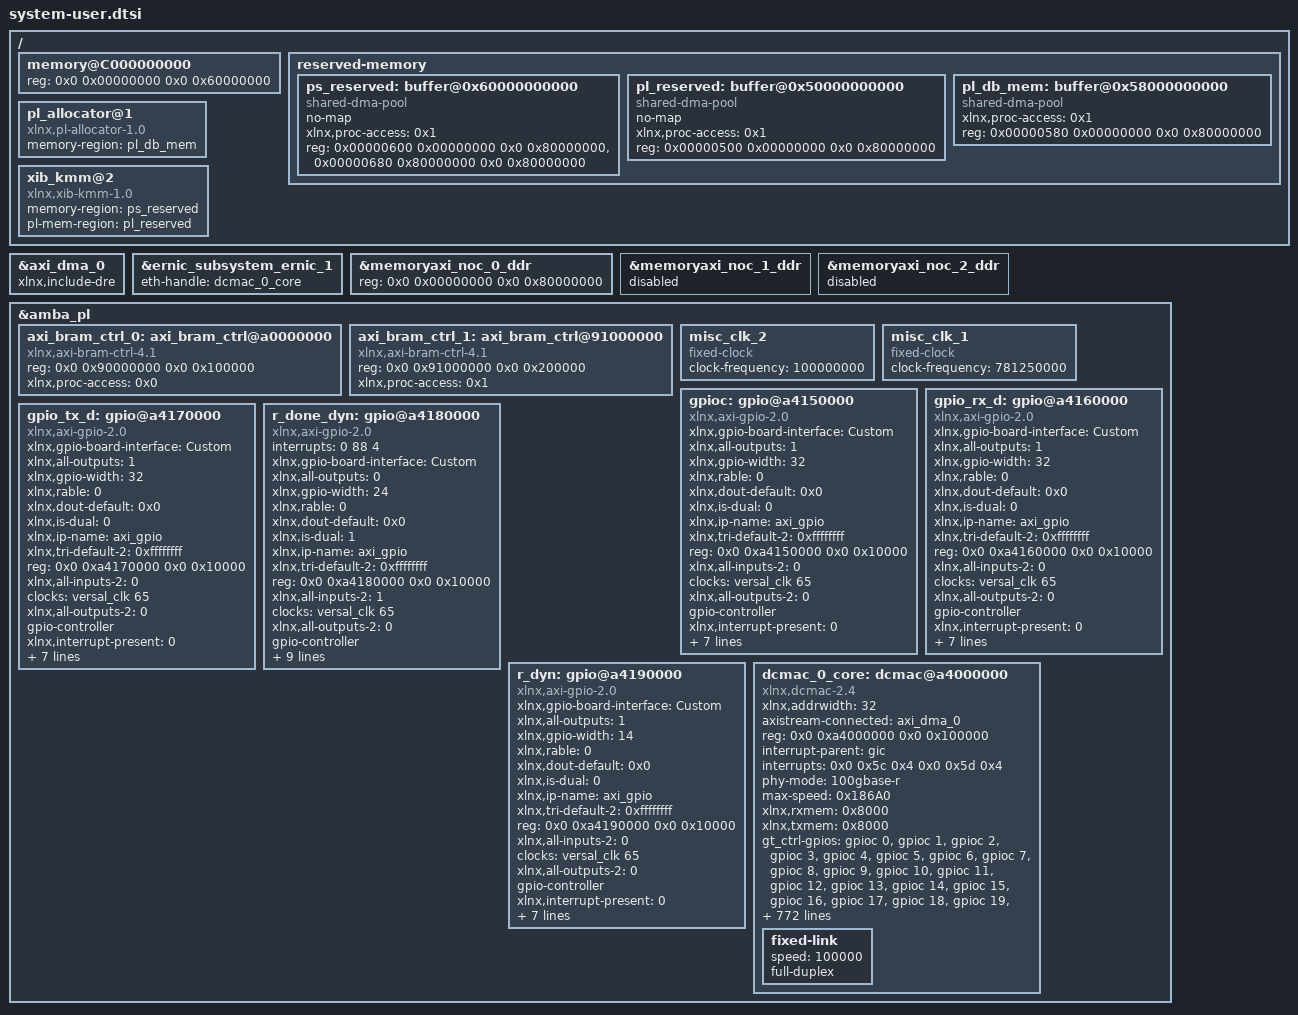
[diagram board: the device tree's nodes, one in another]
/ {
	memory@C000000000 {
		device_type = "memory";
		reg = <0x0 0x00000000 0x0 0x60000000>;
	};
	reserved-memory {
		#address-cells = <2>;
		#size-cells = <2>;
		ranges;

		/*ps_reserved: buffer@0x60000000 {
			compatible = "shared-dma-pool";
                        no-map;
			xlnx,proc-access = <0x1>;
			reg = <0x00000000 0x60000000 0x0 0x20000000>;
        	};*/

		ps_reserved: buffer@0x60000000000 {
			compatible = "shared-dma-pool";
                        no-map;
			xlnx,proc-access = <0x1>;
                        reg = <0x00000600 0x00000000 0x0 0x80000000>, <0x00000680 0x80000000 0x0 0x80000000>;
        	};

		/*pl_reserved: buffer@0x400000000 {
			compatible = "shared-dma-pool";
                        no-map;
			xlnx,proc-access = <0x1>;
			reg = <0xC0 0x00000000 0x1 0x7F000000>;
		};*/

		pl_reserved: buffer@0x50000000000 {
			compatible = "shared-dma-pool";
                        no-map;
			xlnx,proc-access = <0x1>;
                        reg = <0x00000500 0x00000000 0x0 0x80000000>;
                };

		/*pl_db_mem: buffer@0x45F000000 {
			compatible = "shared-dma-pool";
                        //no-map;
			xlnx,proc-access = <0x1>;
			reg = <0xC1 0x7F000000 0x0 0x1000000>;
		};*/

		pl_db_mem: buffer@0x58000000000 {
			compatible = "shared-dma-pool";
                        //no-map;
			xlnx,proc-access = <0x1>;
			reg = <0x00000580 0x00000000 0x0 0x80000000>;
		};
	};

	pl_allocator@1 {
		compatible = "xlnx,pl-allocator-1.0";
		memory-region = <&pl_db_mem>;
	};

	xib_kmm@2 {
		compatible = "xlnx,xib-kmm-1.0";
		memory-region = <&ps_reserved>;
		pl-mem-region = <&pl_reserved>;
	};
};
/*&cips_block_axi_gpio_gt_reset_mask {
	compatible = "xlnx,axi-gpio-2.0";
};
&cips_block_gtctrl {
	compatible = "xlnx,axi-gpio-2.0";
};
*/

&axi_dma_0 {
	xlnx,include-dre ;
};

&ernic_subsystem_ernic_1 {
	interrupt-names = "xrnic_intr0";
	eth-handle = <&dcmac_0_core>;
        //xlnx,num-qp = <0x800>;
};

&memoryaxi_noc_0_ddr {
	reg = <0x0 0x00000000 0x0 0x80000000>;
};
&memoryaxi_noc_1_ddr {
        status = "disabled";
};

&memoryaxi_noc_2_ddr {
        status = "disabled";
};

&amba_pl {
        axi_bram_ctrl_0: axi_bram_ctrl@a0000000 {
                compatible = "xlnx,axi-bram-ctrl-4.1";
                reg = <0x0 0x90000000 0x0 0x100000>;
                xlnx,proc-access = <0x0>;
        };
        axi_bram_ctrl_1: axi_bram_ctrl@91000000 {
                compatible = "xlnx,axi-bram-ctrl-4.1";
                reg = <0x0 0x91000000 0x0 0x200000>;
                xlnx,proc-access = <0x1>;
        };
	misc_clk_2: misc_clk_2 {
	            compatible = "fixed-clock";
		    clock-frequency = <100000000>;
		    #clock-cells = <0>;
        };
	misc_clk_1: misc_clk_1 {
		compatible = "fixed-clock";
		clock-frequency = <781250000>;
		#clock-cells = <0>;
	};
	/*misc_clk_0: misc_clk_0 {
		compatible = "fixed-clock";
		clock-frequency = <390625000>;
		#clock-cells = <0>;
	};*/
	gpioc: gpio@a4150000 {
		xlnx,gpio-board-interface = "Custom";
		compatible = "xlnx,axi-gpio-2.0" , "xlnx,xps-gpio-1.00.a" , "xlnx,xps-gpio-1.00.a";
		xlnx,all-outputs = <1>;
		#gpio-cells = <2>;
		xlnx,gpio-width = <32>;
		xlnx,rable = <0>;
		xlnx,dout-default = <0x0>;
		xlnx,is-dual = <0>;
		xlnx,ip-name = "axi_gpio";
		xlnx,tri-default-2 = <0xffffffff>;
		reg = <0x0 0xa4150000 0x0 0x10000>;
		xlnx,all-inputs-2 = <0>;
		clocks = <&versal_clk 65>;
		xlnx,all-outputs-2 = <0>;
		gpio-controller;
		xlnx,interrupt-present = <0>;
		xlnx,gpio2-board-interface = "Custom";
		xlnx,edk-iptype = "PERIPHERAL";
		xlnx,dout-default-2 = <0x0>;
		status = "okay";
		xlnx,gpio2-width = <32>;
		clock-names = "s_axi_aclk";
		xlnx,tri-default = <0xffffffff>;
		xlnx,name = "gpio1";
		xlnx,all-inputs = <0>;
	};

	gpio_rx_d: gpio@a4160000 {
		xlnx,gpio-board-interface = "Custom";
		compatible = "xlnx,axi-gpio-2.0" , "xlnx,xps-gpio-1.00.a" , "xlnx,xps-gpio-1.00.a";
		xlnx,all-outputs = <1>;
		#gpio-cells = <2>;
		xlnx,gpio-width = <32>;
		xlnx,rable = <0>;
		xlnx,dout-default = <0x0>;
		xlnx,is-dual = <0>;
		xlnx,ip-name = "axi_gpio";
		xlnx,tri-default-2 = <0xffffffff>;
		reg = <0x0 0xa4160000 0x0 0x10000>;
		xlnx,all-inputs-2 = <0>;
		clocks = <&versal_clk 65>;
		xlnx,all-outputs-2 = <0>;
		gpio-controller;
		xlnx,interrupt-present = <0>;
		xlnx,gpio2-board-interface = "Custom";
		xlnx,edk-iptype = "PERIPHERAL";
		xlnx,dout-default-2 = <0x0>;
		status = "okay";
		xlnx,gpio2-width = <32>;
		clock-names = "s_axi_aclk";
		xlnx,tri-default = <0xffffffff>;
		xlnx,name = "gpio_rx_d";
		xlnx,all-inputs = <0>;
	};

	gpio_tx_d: gpio@a4170000 {
		xlnx,gpio-board-interface = "Custom";
		compatible = "xlnx,axi-gpio-2.0" , "xlnx,xps-gpio-1.00.a" , "xlnx,xps-gpio-1.00.a";
		xlnx,all-outputs = <1>;
		#gpio-cells = <2>;
		xlnx,gpio-width = <32>;
		xlnx,rable = <0>;
		xlnx,dout-default = <0x0>;
		xlnx,is-dual = <0>;
		xlnx,ip-name = "axi_gpio";
		xlnx,tri-default-2 = <0xffffffff>;
		reg = <0x0 0xa4170000 0x0 0x10000>;
		xlnx,all-inputs-2 = <0>;
		clocks = <&versal_clk 65>;
		xlnx,all-outputs-2 = <0>;
		gpio-controller;
		xlnx,interrupt-present = <0>;
		xlnx,gpio2-board-interface = "Custom";
		xlnx,edk-iptype = "PERIPHERAL";
		xlnx,dout-default-2 = <0x0>;
		status = "okay";
		xlnx,gpio2-width = <32>;
		clock-names = "s_axi_aclk";
		xlnx,tri-default = <0xffffffff>;
		xlnx,name = "gpio_tx_d";
		xlnx,all-inputs = <0>;
	};

	r_done_dyn: gpio@a4180000 {
		#interrupt-cells = <2>;
		interrupts = < 0 88 4 >;
		xlnx,gpio-board-interface = "Custom";
		compatible = "xlnx,axi-gpio-2.0" , "xlnx,xps-gpio-1.00.a" , "xlnx,xps-gpio-1.00.a";
		xlnx,all-outputs = <0>;
		#gpio-cells = <2>;
		xlnx,gpio-width = <24>;
		//interrupt-parent = <&imux>;
		xlnx,rable = <0>;
		xlnx,dout-default = <0x0>;
		xlnx,is-dual = <1>;
		xlnx,ip-name = "axi_gpio";
		xlnx,tri-default-2 = <0xffffffff>;
		reg = <0x0 0xa4180000 0x0 0x10000>;
		xlnx,all-inputs-2 = <1>;
		clocks = <&versal_clk 65>;
		xlnx,all-outputs-2 = <0>;
		gpio-controller;
		xlnx,interrupt-present = <1>;
		xlnx,gpio2-board-interface = "Custom";
		xlnx,edk-iptype = "PERIPHERAL";
		xlnx,dout-default-2 = <0x0>;
		status = "okay";
		xlnx,gpio2-width = <24>;
		clock-names = "s_axi_aclk";
		interrupt-controller;
		interrupt-names = "ip2intc_irpt";
		xlnx,tri-default = <0xffffffff>;
		xlnx,name = "r_done_dyn";
		xlnx,all-inputs = <1>;
	};

	r_dyn: gpio@a4190000 {
		xlnx,gpio-board-interface = "Custom";
		compatible = "xlnx,axi-gpio-2.0" , "xlnx,xps-gpio-1.00.a" , "xlnx,xps-gpio-1.00.a";
		xlnx,all-outputs = <1>;
		#gpio-cells = <2>;
		xlnx,gpio-width = <14>;
		xlnx,rable = <0>;
		xlnx,dout-default = <0x0>;
		xlnx,is-dual = <0>;
		xlnx,ip-name = "axi_gpio";
		xlnx,tri-default-2 = <0xffffffff>;
		reg = <0x0 0xa4190000 0x0 0x10000>;
		xlnx,all-inputs-2 = <0>;
		clocks = <&versal_clk 65>;
		xlnx,all-outputs-2 = <0>;
		gpio-controller;
		xlnx,interrupt-present = <0>;
		xlnx,gpio2-board-interface = "Custom";
		xlnx,edk-iptype = "PERIPHERAL";
		xlnx,dout-default-2 = <0x0>;
		status = "okay";
		xlnx,gpio2-width = <32>;
		clock-names = "s_axi_aclk";
		xlnx,tri-default = <0xffffffff>;
		xlnx,name = "r_dyn";
		xlnx,all-inputs = <0>;
	};

        dcmac_0_core: dcmac@a4000000 {
                      xlnx,addrwidth = <32>;
                      axistream-connected = <&axi_dma_0>;
                      reg = <0x0 0xa4000000 0x0 0x100000>;
                      interrupt-parent = <&gic>;
                      interrupts = <0x0 0x5c 0x4 0x0 0x5d 0x4>;
                      phy-mode = "100gbase-r"; /* Interface mode specification */
                      max-speed = <0x186A0>;
                      xlnx,rxmem = <0x8000>;
                      xlnx,txmem = <0x8000>;
                      gt_ctrl-gpios = <&gpioc 0 0>, <&gpioc 1 0>, <&gpioc 2 0>, <&gpioc 3 0>, <&gpioc 4 0>, <&gpioc 5 0>, <&gpioc 6 0>, <&gpioc 7 0>,
                      <&gpioc 8 0>, <&gpioc 9 0>, <&gpioc 10 0>, <&gpioc 11 0>, <&gpioc 12 0>, <&gpioc 13 0>, <&gpioc 14 0>, <&gpioc 15 0>,
                      <&gpioc 16 0>, <&gpioc 17 0>, <&gpioc 18 0>, <&gpioc 19 0>, <&gpioc 20 0>, <&gpioc 21 0>, <&gpioc 22 0>, <&gpioc 23 0>,
                      <&gpioc 24 0>, <&gpioc 25 0>, <&gpioc 26 0>, <&gpioc 27 0>, <&gpioc 28 0>, <&gpioc 29 0>, <&gpioc 30 0>, <&gpioc 31 0>;

                      gt_rx_dpath-gpios = <&gpio_rx_d 0 0>, <&gpio_rx_d 1 0>, <&gpio_rx_d 2 0>, <&gpio_rx_d 3 0>, <&gpio_rx_d 4 0>, <&gpio_rx_d 5 0>, <&gpio_rx_d 6 0>, <&gpio_rx_d 7 0>,
                      <&gpio_rx_d 8 0>, <&gpio_rx_d 9 0>, <&gpio_rx_d 10 0>, <&gpio_rx_d 11 0>, <&gpio_rx_d 12 0>, <&gpio_rx_d 13 0>, <&gpio_rx_d 14 0>, <&gpio_rx_d 15 0>,
                      <&gpio_rx_d 16 0>, <&gpio_rx_d 17 0>, <&gpio_rx_d 18 0>, <&gpio_rx_d 19 0>, <&gpio_rx_d 20 0>, <&gpio_rx_d 21 0>, <&gpio_rx_d 22 0>;

                      gt_tx_dpath-gpios = <&gpio_tx_d 0 0>, <&gpio_tx_d 1 0>, <&gpio_tx_d 2 0>, <&gpio_tx_d 3 0>, <&gpio_tx_d 4 0>, <&gpio_tx_d 5 0>, <&gpio_tx_d 6 0>, <&gpio_tx_d 7 0>,
                      <&gpio_tx_d 8 0>, <&gpio_tx_d 9 0>, <&gpio_tx_d 10 0>, <&gpio_tx_d 11 0>, <&gpio_tx_d 12 0>, <&gpio_tx_d 13 0>, <&gpio_tx_d 14 0>, <&gpio_tx_d 15 0>,
                      <&gpio_tx_d 16 0>, <&gpio_tx_d 17 0>, <&gpio_tx_d 18 0>, <&gpio_tx_d 19 0>, <&gpio_tx_d 20 0>, <&gpio_tx_d 21 0>, <&gpio_tx_d 22 0>;

                      gt_tx_rst_done-gpios = <&r_done_dyn 0 0>, <&r_done_dyn 1 0>, <&r_done_dyn 2 0>, <&r_done_dyn 3 0>, <&r_done_dyn 4 0>, <&r_done_dyn 5 0>, <&r_done_dyn 6 0>, <&r_done_dyn 7 0>,
                      <&r_done_dyn 8 0>, <&r_done_dyn 9 0>, <&r_done_dyn 10 0>, <&r_done_dyn 11 0>, <&r_done_dyn 12 0>, <&r_done_dyn 13 0>, <&r_done_dyn 14 0>, <&r_done_dyn 15 0>,
                      <&r_done_dyn 16 0>, <&r_done_dyn 17 0>, <&r_done_dyn 18 0>, <&r_done_dyn 19 0>, <&r_done_dyn 20 0>, <&r_done_dyn 21 0>, <&r_done_dyn 22 0>, <&r_done_dyn 23 0>;

                      gt_rx_rst_done-gpios =  <&r_done_dyn 24 0>, <&r_done_dyn 25 0>, <&r_done_dyn 26 0>, <&r_done_dyn 27 0>,
                      <&r_done_dyn 28 0>, <&r_done_dyn 29 0>, <&r_done_dyn 30 0>, <&r_done_dyn 31 0>, <&r_done_dyn 32 0>, <&r_done_dyn 33 0>,
                      <&r_done_dyn 34 0>, <&r_done_dyn 35 0>, <&r_done_dyn 36 0>, <&r_done_dyn 37 0>, <&r_done_dyn 38 0>, <&r_done_dyn 39 0>,
                      <&r_done_dyn 40 0>, <&r_done_dyn 41 0>, <&r_done_dyn 42 0>, <&r_done_dyn 43 0>, <&r_done_dyn 44 0>, <&r_done_dyn 45 0>,
                      <&r_done_dyn 46 0>, <&r_done_dyn 47 0>;

                      gt_rsts-gpios = <&r_dyn 0 0>, <&r_dyn 1 0>, <&r_dyn 2 0>, <&r_dyn 3 0>, <&r_dyn 4 0>, <&r_dyn 5 0>, <&r_dyn 6 0>, <&r_dyn 7 0>,
                      <&r_dyn 8 0>, <&r_dyn 9 0>, <&r_dyn 10 0>, <&r_dyn 11 0>, <&r_dyn 12 0>, <&r_dyn 13 0>;

	              xlnx,gt-ch0-rx-user-data-width-c0 = <80>;
	              xlnx,gt-mode-0 = "NRZ";
	              xlnx,gt-ch0-rx-user-data-width-c1 = <80>;
	              xlnx,gt-mode-1 = "PAM4";
	              xlnx,mac-port5-enable-c0 = <0>;
	              xlnx,gt-mode-2 = "PAM4";
	              xlnx,mac-port5-enable-c1 = <1>;
	              xlnx,gt-mode-3 = "PAM4";
	              xlnx,mac-port0-rx-etype-gcp-c0 = <0x8808>;
	              xlnx,mac-port5-tx-sa-gpp-c0 = <0x0>;
	              xlnx,gt-mode-4 = "PAM4";
	              xlnx,mac-port0-rx-etype-gcp-c1 = <0x8808>;
	              xlnx,mac-port5-tx-sa-gpp-c1 = <0x0>;
	              xlnx,mac-port2-rx-etype-gcp-c0 = <0x8808>;
	              xlnx,gt-ch0-tx-int-data-width-c0 = <80>;
	              xlnx,mac-port1-rx-flow-c0 = <0>;
	              xlnx,mac-port2-rx-etype-gcp-c1 = <0x8808>;
	              xlnx,gt-ch0-tx-int-data-width-c1 = <80>;
	              xlnx,mac-port4-rx-etype-gcp-c0 = <0x8808>;
	              xlnx,mac-port3-tx-insert-c0 = <0>;
	              xlnx,mac-port1-rx-flow-c1 = <0>;
	              xlnx,mac-port4-rx-etype-gcp-c1 = <0x8808>;
	              xlnx,mac-port3-tx-insert-c1 = <1>;
	              xlnx,mac-port2-tx-ethertype-ppp-c0 = <0x8808>;
	              xlnx,gt-ch1-txprogdiv-freq-val-c0 = <0x266ac338>;
	              xlnx,mac-port2-tx-ethertype-ppp-c1 = <0x8808>;
	              xlnx,gt-ch1-txprogdiv-freq-val-c1 = <0x266ac338>;
	              xlnx,gt-ch2-rx-data-decoding-c0 = "RAW";
	              xlnx,port5-1588v2-operation-mode-c0 = "No , operation";
	              xlnx,gt-ch2-rx-data-decoding-c1 = "RAW";
	              xlnx,diffclk-board-interface = "Custom";
	              xlnx,port5-1588v2-operation-mode-c1 = "No , operation";
	              xlnx,oth-pcs-port0-config3-c0 = "N/A";
	              xlnx,mac-port4-tx-sa-ppp-c0 = <0x0>;
	              xlnx,oth-pcs-port0-config3-c1 = "100CAUI-4";
	              xlnx,mac-port4-tx-sa-ppp-c1 = <0x0>;
	              xlnx,mac-port4-rx-pause-da-ucast-c0 = <0x0>;
	              xlnx,mac-port4-rx-pause-da-ucast-c1 = <0x0>;
	              xlnx,mac-port0-rx-opcode-min-pcp-c0 = <0x0>;
	              xlnx,mac-port0-rx-opcode-min-pcp-c1 = <0x0>;
	              xlnx,overclocking = <0>;
	              xlnx,mac-port3-preemption-c0 = <0>;
	              xlnx,mac-port2-rx-opcode-max-pcp-c0 = <0xffff>;
	              xlnx,mac-port3-preemption-c1 = <0>;
	              xlnx,mac-port2-rx-opcode-max-pcp-c1 = <0xffff>;
	              xlnx,gt-ch0-tx-pll-type-c0 = "LCPLL";
	              xlnx,mac-port0-tx-opcode-ppp-c0 = <0x101>;
	              xlnx,gt-ch0-tx-pll-type-c1 = "LCPLL";
	              xlnx,oth-pcs-port2-config4-c0 = "N/A";
	              xlnx,mac-port0-tx-opcode-ppp-c1 = <0x101>;
	              xlnx,mac-port2-tx-ethertype-gpp-c0 = <0x8808>;
	              xlnx,oth-pcs-port2-config4-c1 = "100CAUI-4";
	              xlnx,mac-port4-config-c0 = "N/A";
	              xlnx,mac-port2-tx-ethertype-gpp-c1 = <0x8808>;
	              xlnx,num-gt-channels-port0 = <4>;
	              xlnx,mac-port4-config-c1 = "N/A";
	              xlnx,num-gt-channels-port1 = <0>;
	              xlnx,num-gt-channels-port2 = <0>;
	              xlnx,mac-port4-tx-sa-gpp-c0 = <0x0>;
	              xlnx,num-gt-channels-port3 = <0>;
	              xlnx,mac-port4-tx-sa-gpp-c1 = <0x0>;
	              xlnx,num-gt-channels-port4 = <0>;
	              xlnx,mac-port3-rx-pause-da-mcast-c0 = <0x180 0xc2000001>;
	              xlnx,num-gt-channels-port5 = <0>;
	              xlnx,port0-1588v2-operation-mode-c0 = "No , operation";
	              xlnx,mac-port3-rx-pause-da-mcast-c1 = <0x180 0xc2000001>;
	              xlnx,mac-port2-tx-insert-c0 = <0>;
	              xlnx,gt-ch2-rx-outclk-source-c0 = "RXPROGDIVCLK";
	              xlnx,port2-1588v2-clocking-c0 = "Ordinary/Boundary , Clock";
	              xlnx,port0-1588v2-operation-mode-c1 = "No , operation";
	              xlnx,mac-port2-tx-insert-c1 = <1>;
	              xlnx,name = "dcmac_0_core";
	              xlnx,mac-port0-rx-opcode-min-gcp-c0 = <0x0>;
	              xlnx,mac-port2-rx-flow-c0 = <0>;
	              xlnx,gt-ch2-txprogdiv-freq-source-c0 = "LCPLL";
	              xlnx,gt-ch2-rx-outclk-source-c1 = "RXPROGDIVCLK";
	              xlnx,port2-1588v2-clocking-c1 = "Ordinary/Boundary , Clock";
	              xlnx,mac-port0-rx-opcode-min-gcp-c1 = <0x0>;
	              xlnx,mac-port2-rx-flow-c1 = <0>;
	              xlnx,gt-ch2-txprogdiv-freq-source-c1 = "LCPLL";
	              xlnx,mac-port0-rx-etype-ppp-c0 = <0x8808>;
	              xlnx,mac-port0-rx-etype-ppp-c1 = <0x8808>;
	              xlnx,gt-drp-clk-c0 = <100>;
	              xlnx,mac-port3-tx-sa-ppp-c0 = <0x0>;
	              xlnx,gt-mode-dyn = "MIX";
	              xlnx,mac-port2-rx-etype-ppp-c0 = <0x8808>;
	              xlnx,mac-port2-rx-opcode-max-gcp-c0 = <0xffff>;
	              xlnx,gt-drp-clk-c1 = <100>;
	              xlnx,gt-ch2-tx-user-data-width-c0 = <80>;
	              xlnx,mac-port3-tx-sa-ppp-c1 = <0x0>;
	              xlnx,mac-port2-rx-etype-ppp-c1 = <0x8808>;
	              xlnx,mac-port2-rx-opcode-max-gcp-c1 = <0xffff>;
	              xlnx,gt-ch2-tx-user-data-width-c1 = <80>;
	              xlnx,oth-pcs-port1-config3-c0 = "N/A";
	              xlnx,mac-port4-rx-etype-ppp-c0 = <0x8808>;
	              xlnx,mac-port0-tx-opcode-gpp-c0 = <0x1>;
	              xlnx,oth-pcs-port1-config3-c1 = "100CAUI-4";
	              xlnx,mac-port5-tx-da-ppp-c0 = <0x180 0xc2000001>;
	              xlnx,mac-port4-rx-etype-ppp-c1 = <0x8808>;
	              xlnx,mac-port0-tx-opcode-gpp-c1 = <0x1>;
	              xlnx,gt-ch3-txprogdiv-freq-enable-c0;
	              xlnx,mac-port5-tx-da-ppp-c1 = <0x180 0xc2000001>;
	              xlnx,gt-ch3-txprogdiv-freq-enable-c1;
	              xlnx,mac-port2-tx-opcode-ppp-c0 = <0x101>;
	              xlnx,mac-port5-rx-pause-sa-c0 = <0x0>;
	              xlnx,mac-port3-tx-ethertype-ppp-c0 = <0x8808>;
	              xlnx,mac-port2-tx-opcode-ppp-c1 = <0x101>;
	              xlnx,mac-port5-rx-pause-sa-c1 = <0x0>;
	              xlnx,gt-ch1-rx-buffer-mode-c0 = <1>;
	              xlnx,port5-1588v2-clocking-c0 = "Ordinary/Boundary , Clock";
	              xlnx,mac-port3-tx-ethertype-ppp-c1 = <0x8808>;
	              xlnx,gt-ch1-rx-buffer-mode-c1 = <1>;
	              xlnx,port5-1588v2-clocking-c1 = "Ordinary/Boundary , Clock";
	              xlnx,gt-ch3-rx-data-decoding-c0 = "RAW";
	              xlnx,gt-ch1-tx-buffer-mode-c0 = <1>;
	              clock-names = "rx_axi_clk" , "rx_core_clk" , "rx_flexif_clk" , "rx_macif_clk" , "s_axi_aclk" , "ts_clk" , "tx_axi_clk" , "tx_core_clk" , "tx_flexif_clk" , "tx_macif_clk";
	              xlnx,gt-ch3-rx-data-decoding-c1 = "RAW";
	              xlnx,gt-ch1-tx-buffer-mode-c1 = <1>;
	              xlnx,mac-port0-enable-c0 = <1>;
	              xlnx,mac-port1-rx-opcode-ppp-c0 = <0x101>;
	              xlnx,gt-ch2-rxprogdiv-freq-source-c0 = "LCPLL";
	              xlnx,mac-port0-enable-c1 = <1>;
	              xlnx,mac-port1-rx-opcode-ppp-c1 = <0x101>;
	              xlnx,gtm-group-select2-c0 = "GTM_DUAL_X0Y0";
	              xlnx,gt-ch2-rxprogdiv-freq-source-c1 = "LCPLL";
	              xlnx,gt-ch1-tx-int-data-width-c0 = <80>;
	              xlnx,gtm-group-select2-c1 = "GTM_DUAL_X0Y0";
	              xlnx,gt-ch1-tx-int-data-width-c1 = <80>;
	              xlnx,ethernet-board-interface = "Custom";
	              xlnx,oth-pcs-port3-config4-c0 = "N/A";
	              xlnx,mac-port0-rx-etype-gpp-c0 = <0x8808>;
	              xlnx,oth-pcs-port3-config4-c1 = "100CAUI-4";
	              xlnx,mac-port0-rx-etype-gpp-c1 = <0x8808>;
	              xlnx,mac-port3-tx-sa-gpp-c0 = <0x0>;
	              xlnx,mac-port2-rx-etype-gpp-c0 = <0x8808>;
	              xlnx,data-rate-cfg-0 = "100G";
	              xlnx,oth-pcs-port0-config2-c0 = "N/A";
	              xlnx,mac-port3-tx-sa-gpp-c1 = <0x0>;
	              xlnx,mac-port2-enable-time-stamping-c0 = <0>;
	              xlnx,mac-port2-rx-etype-gpp-c1 = <0x8808>;
	              xlnx,num-gt-channels-port5-con1 = <0>;
	              xlnx,oth-pcs-port0-config2-c1 = "100CAUI-4";
	              xlnx,mac-port4-rx-etype-gpp-c0 = <0x8808>;
	              xlnx,mac-port2-enable-time-stamping-c1 = <0>;
	              xlnx,num-gt-channels-port5-con2 = <0>;
	              xlnx,gt-ch3-rxprogdiv-freq-enable-c0;
	              xlnx,mac-port5-tx-da-gpp-c0 = <0x180 0xc2000001>;
	              xlnx,mac-port4-rx-etype-gpp-c1 = <0x8808>;
	              xlnx,mac-port1-tx-insert-c0 = <0>;
	              xlnx,num-gt-channels-port5-con3 = <0>;
	              xlnx,gt-ch3-rxprogdiv-freq-enable-c1;
	              xlnx,mac-port5-tx-da-gpp-c1 = <0x180 0xc2000001>;
	              xlnx,mac-port1-tx-insert-c1 = <1>;
	              xlnx,num-gt-channels-port5-con4 = <0>;
	              xlnx,phy-operating-mode-c0 = "N/A";
	              xlnx,mac-port5-rx-pause-da-ucast-c0 = <0x0>;
	              xlnx,mac-port2-tx-opcode-gpp-c0 = <0x1>;
	              xlnx,gt-ch3-tx-refclk-frequency-c0 = <0x13356219>;
	              xlnx,gt-ch2-rxprogdiv-freq-val-c0 = <0x266ac338>;
	              xlnx,gt-ch0-tx-line-rate-c0 = <0x9d5b34>;
	              xlnx,mac-port5-rx-pause-da-ucast-c1 = <0x0>;
	              xlnx,mac-port3-tx-ethertype-gpp-c0 = <0x8808>;
	              xlnx,mac-port3-rx-flow-c0 = <0>;
	              xlnx,mac-port2-tx-opcode-gpp-c1 = <0x1>;
	              xlnx,num-gt-channels-port2-con1 = <0>;
	              xlnx,gt-ch3-tx-refclk-frequency-c1 = <0x9502f90>;
	              xlnx,gt-ch2-rxprogdiv-freq-val-c1 = <0x266ac338>;
	              xlnx,gt-ch0-tx-line-rate-c1 = <0x9d5b34>;
	              xlnx,mac-port3-tx-ethertype-gpp-c1 = <0x8808>;
	              xlnx,mac-port3-rx-flow-c1 = <0>;
	              xlnx,mac-port1-rx-opcode-min-pcp-c0 = <0x0>;
	              xlnx,num-gt-channels-port2-con2 = <0>;
	              lnx,gt-ch2-tx-line-rate-c0 = <0x9d5b34>;
	              xlnx,mac-port4-tx-opcode-ppp-c0 = <0x101>;
	              xlnx,mac-port2-tx-sa-ppp-c0 = <0x0>;
	              xlnx,mac-port1-rx-opcode-min-pcp-c1 = <0x0>;
	              xlnx,num-gt-channels-port2-con3 = <0>;
	              xlnx,gt-ch2-tx-line-rate-c1 = <0x9d5b34>;
	              xlnx,mac-port4-tx-opcode-ppp-c1 = <0x101>;
	              xlnx,mac-port2-tx-sa-ppp-c1 = <0x0>;
	              xlnx,num-gt-channels-port2-con4 = <0>;
	              xlnx,mac-port1-rx-opcode-gpp-c0 = <0x1>;
	              xlnx,mac-port4-tx-da-ppp-c0 = <0x180 0xc2000001>;
	              xlnx,mac-port3-rx-opcode-max-pcp-c0 = <0xffff>;
	              xlnx,mac-port1-rx-opcode-gpp-c1 = <0x1>;
	              xlnx,oth-pcs-port2-config3-c0 = "N/A";
	              xlnx,mac-port4-tx-da-ppp-c1 = <0x180 0xc2000001>;
	              xlnx,mac-port3-rx-opcode-max-pcp-c1 = <0xffff>;
	              xlnx,gt-ch2-tx-refclk-frequency-c0 = <0x13356219>;
	              xlnx,oth-pcs-port2-config3-c1 = "100CAUI-4";
	              xlnx,mac-port3-rx-opcode-ppp-c0 = <0x101>;
	              xlnx,gt-ch3-rx-outclk-source-c0 = "RXPROGDIVCLK";
	              xlnx,gt-ch2-tx-refclk-frequency-c1 = <0x9502f90>;
	              xlnx,mac-port3-rx-opcode-ppp-c1 = <0x101>;
	              xlnx,gt-ch3-tx-pll-type-c0 = "LCPLL";
	              xlnx,gt-ch3-rx-outclk-source-c1 = "RXPROGDIVCLK";
	              xlnx,gt-ch3-tx-pll-type-c1 = "LCPLL";
	              xlnx,gt-ch0-tx-user-data-width-c0 = <80>;
	              xlnx,port4-1588v2-operation-mode-c0 = "No , operation";
	              xlnx,gt-ch0-tx-user-data-width-c1 = <80>;
	              xlnx,port4-1588v2-operation-mode-c1 = "No , operation";
	              xlnx,mac-port5-rx-strip-c0 = <0>;
	              xlnx,mac-port4-preemption-c0 = <0>;
	              xlnx,mac-port1-rx-pause-sa-c0 = <0x0>;
	              xlnx,mac-port5-rx-strip-c1 = <0>;
	              xlnx,mac-port4-preemption-c1 = <0>;
	              xlnx,mac-port1-rx-pause-sa-c1 = <0x0>;
	              xlnx,gt-ch1-tx-refclk-frequency-c0 = <0x13356219>;
	              xlnx,mac-port4-rx-pause-da-mcast-c0 = <0x180 0xc2000001>;
	              xlnx,gt-ch1-tx-refclk-frequency-c1 = <0x9502f90>;
	              xlnx,mac-port4-rx-pause-da-mcast-c1 = <0x180 0xc2000001>;
	              xlnx,mac-port1-rx-opcode-min-gcp-c0 = <0x0>;
	              xlnx,oth-pcs-port4-config4-c0 = "N/A";
	              xlnx,mac-port4-tx-opcode-gpp-c0 = <0x1>;
	              xlnx,mac-port2-tx-sa-gpp-c0 = <0x0>;
	              xlnx,mac-port1-rx-opcode-min-gcp-c1 = <0x0>;
	              xlnx,oth-pcs-port4-config4-c1 = "100CAUI-4";
	              xlnx,mac-port4-tx-opcode-gpp-c1 = <0x1>;
	              xlnx,mac-port4-tx-ethertype-ppp-c0 = <0x8808>;
	              xlnx,mac-port2-tx-sa-gpp-c1 = <0x0>;
	              xlnx,mac-port4-tx-ethertype-ppp-c1 = <0x8808>;
	              xlnx,fec-slice5-cfg-c0 = "N/A";
	              xlnx,oth-pcs-port1-config2-c0 = "N/A";
	              xlnx,mac-port4-tx-da-gpp-c0 = <0x180 0xc2000001>;
	              xlnx,mac-port3-rx-opcode-max-gcp-c0 = <0xffff>;
	              xlnx,fec-slice5-cfg-c1 = "N/A";
	              xlnx,mac-port0-tx-insert-c0 = <1>;
	              xlnx,gt-ch0-tx-refclk-frequency-c0 = <0x13356219>;
	              xlnx,oth-pcs-port1-config2-c1 = "100CAUI-4";
	              xlnx,mac-port4-tx-da-gpp-c1 = <0x180 0xc2000001>;
	              xlnx,mac-port3-rx-opcode-max-gcp-c1 = <0xffff>;
	              xlnx,mac-port0-tx-insert-c1 = <1>;
	              xlnx,gt-ch0-tx-refclk-frequency-c1 = <0x9502f90>;
	              xlnx,mac-port3-rx-opcode-gpp-c0 = <0x1>;
	              xlnx,mac-port3-rx-opcode-gpp-c1 = <0x1>;
	              xlnx,mac-port2-enable-c0 = <0>;
	              xlnx,gt-pipeline-stages = <0>;
	              xlnx,mac-port2-enable-c1 = <1>;
	              xlnx,mac-port5-rx-opcode-ppp-c0 = <0x101>;
	              xlnx,mac-port4-rx-flow-c0 = <0>;
	              xlnx,mac-port1-tx-sa-ppp-c0 = <0x0>;
	              xlnx,mac-port5-rx-opcode-ppp-c1 = <0x101>;
	              xlnx,mac-port4-rx-flow-c1 = <0>;
	              xlnx,mac-port1-tx-sa-ppp-c1 = <0x0>;
	              xlnx,gt-ch3-rx-user-data-width-c0 = <80>;
	              xlnx,gt-ch3-rx-user-data-width-c1 = <80>;
	              xlnx,gt-ch0-rx-int-data-width-c0 = <80>;
	              xlnx,mac-port3-tx-da-ppp-c0 = <0x180 0xc2000001>;
	              xlnx,gt-ch0-rx-int-data-width-c1 = <80>;
	              xlnx,mac-port3-tx-da-ppp-c1 = <0x180 0xc2000001>;
	              xlnx,gtm-group-select1-c0 = "GTM_DUAL_X0Y0";
	              xlnx,gt-ch0-rxprogdiv-freq-val-c0 = <0x266ac338>;
	              xlnx,gtm-group-select1-c1 = "GTM_DUAL_X0Y0";
	              xlnx,gt-ch1-txprogdiv-freq-source-c0 = "LCPLL";
	              xlnx,gt-ch1-rx-line-rate-c0 = <0x9d5b34>;
	              xlnx,gt-ch0-rxprogdiv-freq-val-c1 = <0x266ac338>;
	              xlnx,oth-pcs-port3-config3-c0 = "N/A";
	              xlnx,include-auto-neg-lt-logic-c0 = "None";
	              xlnx,gt-ch2-tx-int-data-width-c0 = <80>;
	              xlnx,gt-ch1-txprogdiv-freq-source-c1 = "LCPLL";
	              xlnx,gt-ch1-rx-line-rate-c1 = <0x9d5b34>;
	              xlnx,full-density-mode = <0>;
	              xlnx,oth-pcs-port3-config3-c1 = "100CAUI-4";
	              xlnx,include-auto-neg-lt-logic-c1 = "None";
	              xlnx,gt-ch3-rx-line-rate-c0 = <0x9d5b34>;
	              xlnx,gt-ch2-tx-int-data-width-c1 = <80>;
	              xlnx,gt-ch0-rx-buffer-mode-c0 = <1>;
	              xlnx,mac-port4-tx-ethertype-gpp-c0 = <0x8808>;
	              xlnx,fec-slice3-cfg-c0 = "N/A";
	              xlnx,gt-ch3-rx-line-rate-c1 = <0x9d5b34>;
	              xlnx,gt-ch0-rx-buffer-mode-c1 = <1>;
	              xlnx,oth-pcs-port0-config1-c0 = "N/A";
	              xlnx,mac-port4-tx-ethertype-gpp-c1 = <0x8808>;
	              xlnx,fec-slice3-cfg-c1 = "N/A";
	              xlnx,gt-ch0-tx-buffer-mode-c0 = <1>;
	              xlnx,oth-pcs-port0-config1-c1 = "100CAUI-4";
	              xlnx,gt-ch0-tx-buffer-mode-c1 = <1>;
	              status = "okay";
	              xlnx,num-gt-channels-con4-valid = <0>;
	              xlnx,dcmac-clients-c0 = "N/A";
	              xlnx,gt-ch2-txprogdiv-freq-enable-c0;
	              xlnx,dcmac-clients-c1 = "N/A";
	              xlnx,gt-ch2-txprogdiv-freq-enable-c1;
	              xlnx,mac-port5-rx-opcode-gpp-c0 = <0x1>;
	              xlnx,mac-port1-tx-sa-gpp-c0 = <0x0>;
	              xlnx,mac-port5-rx-opcode-gpp-c1 = <0x1>;
	              xlnx,mac-port1-tx-sa-gpp-c1 = <0x0>;
	              xlnx,lane1-gt-loc-c0 = "X0Y0";
	              xlnx,oth-pcs-port5-config4-c0 = "N/A";
	              xlnx,mac-port2-rx-opcode-min-pcp-c0 = <0x0>;
	              xlnx,lane1-gt-loc-c1 = "X0Y0";
	              xlnx,is-board-project = <1>;
	              xlnx,oth-pcs-port5-config4-c1 = "100CAUI-4";
	              xlnx,mac-port4-rx-strip-c0 = <0>;
	              xlnx,mac-port3-tx-da-gpp-c0 = <0x180 0xc2000001>;
	              xlnx,mac-port2-rx-opcode-min-pcp-c1 = <0x0>;
	              xlnx,mac-port4-rx-strip-c1 = <0>;
	              xlnx,mac-port3-tx-da-gpp-c1 = <0x180 0xc2000001>;
	              xlnx,gt-ch1-rxprogdiv-freq-source-c0 = "LCPLL";
	              xlnx,oth-pcs-port2-config2-c0 = "N/A";
	              xlnx,mac-port1-config-c0 = "N/A";
	              xlnx,gt-ch1-rxprogdiv-freq-source-c1 = "LCPLL";
	              xlnx,oth-pcs-port2-config2-c1 = "100CAUI-4";
	              xlnx,mac-port4-rx-opcode-max-pcp-c0 = <0xffff>;
	              xlnx,mac-port1-config-c1 = "N/A";
	              xlnx,mac-port4-rx-opcode-max-pcp-c1 = <0xffff>;
	              xlnx,fec-slice1-cfg-c0 = "N/A";
	              xlnx,fec-slice1-cfg-c1 = "N/A";
	              xlnx,mac-port0-tx-sa-ppp-c0 = <0x0>;
	              xlnx,mac-port0-tx-sa-ppp-c1 = <0x0>;
	              xlnx,edk-iptype = "PERIPHERAL";
	              xlnx,mac-port5-rx-flow-c0 = <0>;
	              xlnx,mac-port0-rx-pause-da-ucast-c0 = <0x0>;
	              xlnx,mac-port5-tx-ethertype-ppp-c0 = <0x8808>;
	              xlnx,mac-port5-rx-flow-c1 = <0>;
	              xlnx,mac-port0-rx-pause-da-ucast-c1 = <0x0>;
	              xlnx,mac-port2-tx-da-ppp-c0 = <0x180 0xc2000001>;
	              xlnx,num-gt-channels-con3-valid = <0>;
	              xlnx,gt-ch2-rxprogdiv-freq-enable-c0;
	              xlnx,mac-port5-tx-ethertype-ppp-c1 = <0x8808>;
	              xlnx,mac-port2-tx-da-ppp-c1 = <0x180 0xc2000001>;
	              xlnx,gt-ch2-rxprogdiv-freq-enable-c1;
	              xlnx,port0-1588v2-clocking-c0 = "Ordinary/Boundary , Clock";
	              xlnx,port0-1588v2-clocking-c1 = "Ordinary/Boundary , Clock";
	              xlnx,mac-port5-rx-pause-da-mcast-c0 = <0x180 0xc2000001>;
	              xlnx,mac-port4-rx-pause-sa-c0 = <0x0>;
	              xlnx,oth-pcs-port4-config3-c0 = "N/A";
	              xlnx,mac-port5-rx-pause-da-mcast-c1 = <0x180 0xc2000001>;
	              xlnx,mac-port4-rx-pause-sa-c1 = <0x0>;
	              xlnx,gt-ch1-rx-user-data-width-c0 = <80>;
	              xlnx,oth-pcs-port4-config3-c1 = "100CAUI-4";
	              xlnx,mac-port4-enable-c0 = <0>;
	              xlnx,mac-port2-rx-opcode-min-gcp-c0 = <0x0>;
	              xlnx,gt-ch1-rx-user-data-width-c1 = <80>;
	              xlnx,mac-port4-enable-c1 = <1>;
	              xlnx,mac-port1-enable-time-stamping-c0 = <0>;
	              xlnx,mac-port2-rx-opcode-min-gcp-c1 = <0x0>;
	              xlnx,oth-pcs-port1-config1-c0 = "N/A";
	              xlnx,mac-port1-enable-time-stamping-c1 = <0>;
	              xlnx,oth-pcs-port1-config1-c1 = "100CAUI-4";
	              xlnx,num-gt-channels-con0 = <4>;
	              xlnx,enable-phase-fifo = <0>;
	              xlnx,num-gt-channels-con1 = <0>;
	              xlnx,mac-port4-rx-opcode-max-gcp-c0 = <0xffff>;
	              xlnx,mac-port1-rx-etype-pcp-c0 = <0x8808>;
	              xlnx,mac-port5-preemption-c0 = <0>;
	              xlnx,num-gt-channels-con2 = <0>;
	              xlnx,mac-port5-enable-time-stamping-c0 = <0>;
	              xlnx,mac-port4-rx-opcode-max-gcp-c1 = <0xffff>;
	              xlnx,mac-port1-rx-etype-pcp-c1 = <0x8808>;
	              xlnx,mac-port5-preemption-c1 = <0>;
	              xlnx,num-gt-channels-con3 = <0>;
	              xlnx,mac-port5-enable-time-stamping-c1 = <0>;
	              xlnx,mac-port3-rx-etype-pcp-c0 = <0x8808>;
	              xlnx,mac-port0-tx-sa-gpp-c0 = <0x0>;
	              xlnx,port3-1588v2-clocking-c0 = "Ordinary/Boundary , Clock";
	              xlnx,num-gt-channels-con4 = <0>;
	              xlnx,mac-port3-rx-etype-pcp-c1 = <0x8808>;
	              xlnx,mac-port0-tx-sa-gpp-c1 = <0x0>;
	              xlnx,port3-1588v2-operation-mode-c0 = "No , operation";
	              xlnx,port3-1588v2-clocking-c1 = "Ordinary/Boundary , Clock";
	              xlnx,mac-port5-rx-etype-pcp-c0 = <0x8808>;
	              xlnx,gt-ch2-txprogdiv-freq-val-c0 = <0x266ac338>;
	              xlnx,port3-1588v2-operation-mode-c1 = "No , operation";
	              xlnx,mac-port5-tx-ethertype-gpp-c0 = <0x8808>;
	              xlnx,mac-port5-rx-etype-pcp-c1 = <0x8808>;
	              xlnx,mac-port2-tx-da-gpp-c0 = <0x180 0xc2000001>;
	              xlnx,num-gt-channels-con2-valid = <0>;
	              xlnx,gt-ch2-txprogdiv-freq-val-c1 = <0x266ac338>;
	              xlnx,mac-port5-tx-ethertype-gpp-c1 = <0x8808>;
	              xlnx,mac-port2-tx-da-gpp-c1 = <0x180 0xc2000001>;
	              xlnx,gt-ch1-rx-int-data-width-c0 = <80>;
	              xlnx,gt-ch1-rx-int-data-width-c1 = <80>;
	              xlnx,oth-pcs-port3-config2-c0 = "N/A";
	              xlnx,gt-ch0-tx-outclk-source-c0 = "TXPROGDIVCLK";
	              xlnx,oth-pcs-port3-config2-c1 = "100CAUI-4";
	              xlnx,mac-port0-tx-flow-c0 = <1>;
	              xlnx,gt-ch0-tx-outclk-source-c1 = "TXPROGDIVCLK";
	              xlnx,mac-port0-tx-flow-c1 = <0>;
	              xlnx,mac-port0-preemption-c0 = <0>;
	              xlnx,gt-ch3-tx-int-data-width-c0 = <80>;
	              xlnx,mac-port0-preemption-c1 = <0>;
	              xlnx,gt-ch3-tx-int-data-width-c1 = <80>;
	              xlnx,mac-port3-rx-strip-c0 = <0>;
	              xlnx,mac-port1-tx-da-ppp-c0 = <0x180 0xc2000001>;
	              xlnx,mac-port3-rx-strip-c1 = <0>;
	              xlnx,mac-port1-tx-da-ppp-c1 = <0x180 0xc2000001>;
	              xlnx,mac-port1-rx-etype-gcp-c0 = <0x8808>;
	              xlnx,mac-port1-rx-etype-gcp-c1 = <0x8808>;
	              xlnx,mac-port3-rx-etype-gcp-c0 = <0x8808>;
	              xlnx,mac-port3-rx-etype-gcp-c1 = <0x8808>;
	              xlnx,mac-port3-config-c0 = "N/A";
	              xlnx,gt-ch2-tx-pll-type-c0 = "LCPLL";
	              xlnx,mac-port5-rx-etype-gcp-c0 = <0x8808>;
	              xlnx,mac-port3-config-c1 = "N/A";
	              xlnx,gt-ch2-tx-pll-type-c1 = "LCPLL";
	              xlnx,oth-pcs-port5-config3-c0 = "N/A";
	              xlnx,mac-port5-rx-etype-gcp-c1 = <0x8808>;
	              xlnx,num-gt-channels-con1-valid = <0>;
	              xlnx,oth-pcs-port5-config3-c1 = "100CAUI-4";
	              xlnx,num-gt-channels-port4-con1 = <0>;
	              xlnx,mac-port3-rx-opcode-min-pcp-c0 = <0x0>;
	              xlnx,num-gt-channels-port4-con2 = <0>;
	              xlnx,mac-port0-rx-pause-sa-c0 = <0x0>;
	              xlnx,oth-pcs-port2-config1-c0 = "N/A";
	              xlnx,mac-port3-rx-opcode-min-pcp-c1 = <0x0>;
	              xlnx,num-gt-channels-port4-con3 = <0>;
	              xlnx,mac-port0-rx-pause-sa-c1 = <0x0>;
	              xlnx,gt-ch0-tx-data-encoding-c0 = "RAW";
	              xlnx,oth-pcs-port2-config1-c1 = "100CAUI-4";
	              xlnx,num-gt-channels-port4-con4 = <0>;
	              xlnx,gt-ch0-txprogdiv-freq-source-c0 = "LCPLL";
	              xlnx,gt-ch0-tx-data-encoding-c1 = "RAW";
	              xlnx,gt-ch0-txprogdiv-freq-source-c1 = "LCPLL";
	              xlnx,mac-port5-rx-opcode-max-pcp-c0 = <0xffff>;
	              xlnx,num-gt-channels-port1-con1 = <0>;
	              xlnx,mac-port5-rx-opcode-max-pcp-c1 = <0xffff>;
	              compatible = "xlnx,dcmac-2.4";
	              xlnx,num-gt-channels-port1-con2 = <0>;
	              xlnx,mac-port1-tx-da-gpp-c0 = <0x180 0xc2000001>;
	              xlnx,num-gt-channels-port1-con3 = <0>;
	              xlnx,mac-port1-tx-da-gpp-c1 = <0x180 0xc2000001>;
	              xlnx,num-gt-channels-port1-con4 = <0>;
	              xlnx,mac-port1-rx-pause-da-ucast-c0 = <0x0>;
	              xlnx,mac-port1-rx-pause-da-ucast-c1 = <0x0>;
	              xlnx,gt-ch3-tx-user-data-width-c0 = <80>;
	              xlnx,gt-ch1-txprogdiv-freq-enable-c0;
	              xlnx,gt-ch3-tx-user-data-width-c1 = <80>;
	              xlnx,gt-ch1-txprogdiv-freq-enable-c1;
	              xlnx,oth-pcs-port4-config2-c0 = "N/A";
	              xlnx,gt-ch0-txprogdiv-freq-val-c0 = <0x266ac338>;
	              xlnx,oth-pcs-port4-config2-c1 = "100CAUI-4";
	              xlnx,mac-port1-tx-flow-c0 = <0>;
	              xlnx,num-gt-channels-con0-valid = <4>;
	              xlnx,gt-ch0-txprogdiv-freq-val-c1 = <0x266ac338>;
	              xlnx,mac-port0-tx-da-ppp-c0 = <0x180 0xc2000001>;
	              xlnx,mac-port1-tx-flow-c1 = <0>;
	              xlnx,mac-port3-rx-opcode-min-gcp-c0 = <0x0>;
	              xlnx,mac-port0-tx-da-ppp-c1 = <0x180 0xc2000001>;
	              xlnx,mac-port3-rx-opcode-min-gcp-c1 = <0x0>;
	              xlnx,gt-ch0-rxprogdiv-freq-source-c0 = "LCPLL";
	              xlnx,gt-ch0-rxprogdiv-freq-source-c1 = "LCPLL";
	              xlnx,mac-port5-rx-opcode-max-gcp-c0 = <0xffff>;
	              xlnx,mac-port5-rx-opcode-max-gcp-c1 = <0xffff>;
	              xlnx,mac-port1-tx-opcode-ppp-c0 = <0x101>;
	              xlnx,gt-ch1-tx-outclk-source-c0 = "TXPROGDIVCLK";
	              xlnx,mac-port1-tx-opcode-ppp-c1 = <0x101>;
	              xlnx,gt-ch1-tx-outclk-source-c1 = "TXPROGDIVCLK";
	              xlnx,mac-port2-rx-strip-c0 = <0>;
	              xlnx,mac-port0-rx-pause-da-mcast-c0 = <0x180 0xc2000001>;
	              xlnx,mac-port1-rx-etype-ppp-c0 = <0x8808>;
	              xlnx,mac-port2-rx-strip-c1 = <0>;
	              xlnx,gt-ch1-rxprogdiv-freq-enable-c0;
	              xlnx,mac-port0-rx-pause-da-mcast-c1 = <0x180 0xc2000001>;
	              xlnx,mac-port1-rx-etype-ppp-c1 = <0x8808>;
	              xlnx,gt-ch1-rxprogdiv-freq-enable-c1;
	              xlnx,mac-port3-rx-etype-ppp-c0 = <0x8808>;
	              xlnx,mac-port0-rx-opcode-ppp-c0 = <0x101>;
	              xlnx,oth-pcs-port3-config1-c0 = "N/A";
	              xlnx,mac-port3-rx-etype-ppp-c1 = <0x8808>;
	              xlnx,mac-port0-rx-opcode-ppp-c1 = <0x101>;
	              xlnx,gt-ch2-rx-int-data-width-c0 = <80>;
	              xlnx,oth-pcs-port3-config1-c1 = "100CAUI-4";
	              xlnx,mac-port5-rx-etype-ppp-c0 = <0x8808>;
	              xlnx,gt-ch2-rx-int-data-width-c1 = <80>;
	              xlnx,timestamp-clk-period-ns = <4>;
	              xlnx,mac-port5-rx-etype-ppp-c1 = <0x8808>;
	              xlnx,mac-port0-tx-da-gpp-c0 = <0x180 0xc2000001>;
	              xlnx,gt-ch3-rxprogdiv-freq-val-c0 = <0x266ac338>;
	              xlnx,mac-port5-config-c0 = "N/A";
	              xlnx,mac-port0-tx-da-gpp-c1 = <0x180 0xc2000001>;
	              xlnx,gt-ch3-rxprogdiv-freq-val-c1 = <0x266ac338>;
	              xlnx,mac-port5-config-c1 = "N/A";
	              xlnx,dcmac-location-c0 = "DCMAC_X0Y0";
	              xlnx,dcmac-location-c1 = "N/A";
	              xlnx,gt-ch1-tx-data-encoding-c0 = "RAW";
	              xlnx,mac-port1-tx-opcode-gpp-c0 = <0x1>;
	              xlnx,gt-ch1-tx-data-encoding-c1 = "RAW";
	              xlnx,mac-port1-tx-opcode-gpp-c1 = <0x1>;
	              xlnx,gt-group-select-c0 = "X0Y0";
	              xlnx,port2-1588v2-operation-mode-c0 = "No , operation";
	              xlnx,oth-pcs-port5-config2-c0 = "N/A";
	              xlnx,gt-group-select-c1 = "X0Y0";
	              xlnx,port2-1588v2-operation-mode-c1 = "No , operation";
	              xlnx,oth-pcs-port5-config2-c1 = "100CAUI-4";
	              xlnx,mac-port3-tx-opcode-ppp-c0 = <0x101>;
	              xlnx,mac-port2-tx-flow-c0 = <0>;
	              xlnx,mac-port0-enable-time-stamping-c0 = <0>;
	              xlnx,mac-port1-rx-etype-gpp-c0 = <0x8808>;
	              xlnx,mac-port1-preemption-c0 = <0>;
	              xlnx,mac-port3-tx-opcode-ppp-c1 = <0x101>;
	              xlnx,mac-port2-tx-flow-c1 = <0>;
	              xlnx,mac-port0-enable-time-stamping-c1 = <0>;
	              xlnx,mac-port1-rx-etype-gpp-c1 = <0x8808>;
	              xlnx,mac-port1-preemption-c1 = <0>;
	              xlnx,gt-ch1-tx-user-data-width-c0 = <80>;
	              xlnx,mac-port3-rx-etype-gpp-c0 = <0x8808>;
	              xlnx,mac-port0-rx-opcode-gpp-c0 = <0x1>;
	              xlnx,gt-ch1-tx-user-data-width-c1 = <80>;
	              xlnx,mac-port4-rx-opcode-min-pcp-c0 = <0x0>;
	              xlnx,mac-port3-rx-etype-gpp-c1 = <0x8808>;
	              xlnx,mac-port0-rx-opcode-gpp-c1 = <0x1>;
	              xlnx,mac-port5-rx-etype-gpp-c0 = <0x8808>;
	              xlnx,mac-port4-rx-opcode-min-pcp-c1 = <0x0>;
	              xlnx,mac-port4-enable-time-stamping-c0 = <0>;
	              xlnx,mac-port5-rx-etype-gpp-c1 = <0x8808>;
	              xlnx,mac-port4-enable-time-stamping-c1 = <0>;
	              xlnx,mac-port2-rx-opcode-ppp-c0 = <0x101>;
	              xlnx,mac-port3-rx-pause-sa-c0 = <0x0>;
	              xlnx,mac-port2-rx-opcode-ppp-c1 = <0x101>;
	              xlnx,mac-port3-rx-pause-sa-c1 = <0x0>;
	              xlnx,gt-type-c0 = "GTM";
	              xlnx,gt-ch1-tx-line-rate-c0 = <0x9d5b34>;
	              xlnx,gt-type-c1 = "N/A";
	              xlnx,gt-ch1-tx-line-rate-c1 = <0x9d5b34>;
	              xlnx,gt-ch3-tx-line-rate-c0 = <0x9d5b34>;
	              xlnx,gt-ch3-tx-line-rate-c1 = <0x9d5b34>;
	              xlnx,mac-port2-rx-pause-da-ucast-c0 = <0x0>;
	              xlnx,dcmac-data-path-interface-c0 = "391MHz , Upto , 6 , Ports";
	              xlnx,mac-port2-rx-pause-da-ucast-c1 = <0x0>;
	              xlnx,oth-pcs-port4-config1-c0 = "N/A";
	              xlnx,dcmac-data-path-interface-c1 = "N/A";
	              xlnx,mac-port1-enable-c0 = <0>;
	              xlnx,oth-pcs-port4-config1-c1 = "100CAUI-4";
	              xlnx,mac-port1-enable-c1 = <1>;
	              xlnx,mac-port3-tx-opcode-gpp-c0 = <0x1>;
	              xlnx,mac-port1-rx-strip-c0 = <0>;
	              xlnx,gt-ch2-tx-outclk-source-c0 = "TXPROGDIVCLK";
	              xlnx,mac-port3-tx-opcode-gpp-c1 = <0x1>;
	              xlnx,mac-port1-rx-strip-c1 = <0>;
	              xlnx,gt-ch2-tx-outclk-source-c1 = "TXPROGDIVCLK";
	              xlnx,mac-port0-rx-opcode-max-pcp-c0 = <0xffff>;
	              xlnx,mac-port5-tx-opcode-ppp-c0 = <0x101>;
	              xlnx,mac-port4-rx-opcode-min-gcp-c0 = <0x0>;
	              xlnx,mac-port0-rx-opcode-max-pcp-c1 = <0xffff>;
	              xlnx,rable = <0>;
	              xlnx,mac-port5-tx-opcode-ppp-c1 = <0x101>;
	              xlnx,mac-port4-rx-opcode-min-gcp-c1 = <0x0>;
	              xlnx,gt-ref-clk-freq-c0 = <0x13356219>;
	              xlnx,ip-name = "dcmac";
	              xlnx,mac-port2-rx-opcode-gpp-c0 = <0x1>;
	              xlnx,port1-1588v2-clocking-c0 = "Ordinary/Boundary , Clock";
	              xlnx,gt-ref-clk-freq-c1 = <0x13356219>;
	              xlnx,mac-port0-tx-ethertype-ppp-c0 = <0x8808>;
	              xlnx,mac-port2-rx-opcode-gpp-c1 = <0x1>;
	              xlnx,gt-ch1-rxprogdiv-freq-val-c0 = <0x266ac338>;
	              xlnx,port1-1588v2-clocking-c1 = "Ordinary/Boundary , Clock";
	              xlnx,mac-port0-tx-ethertype-ppp-c1 = <0x8808>;
	              xlnx,gt-ch1-rxprogdiv-freq-val-c1 = <0x266ac338>;
	              xlnx,mac-port4-rx-opcode-ppp-c0 = <0x101>;
	              xlnx,gt-ch0-rx-data-decoding-c0 = "RAW";
	              xlnx,mac-port4-rx-opcode-ppp-c1 = <0x101>;
	              xlnx,gt-ch0-rx-data-decoding-c1 = "RAW";
	              xlnx,mac-port3-tx-flow-c0 = <0>;
	              xlnx,mac-port3-tx-flow-c1 = <0>;
	              xlnx,mac-port1-rx-pause-da-mcast-c0 = <0x180 0xc2000001>;
	              xlnx,gt-ch3-rx-buffer-mode-c0 = <1>;
	              xlnx,gt-ch0-txprogdiv-freq-enable-c0;
	              xlnx,fast-sim-mode = <0>;
	              xlnx,mac-port1-rx-pause-da-mcast-c1 = <0x180 0xc2000001>;
	              xlnx,gt-ch3-rx-buffer-mode-c1 = <1>;
	              xlnx,gt-ch0-txprogdiv-freq-enable-c1;
	              xlnx,gt-ch3-tx-buffer-mode-c0 = <1>;
	              xlnx,gt-ch3-tx-buffer-mode-c1 = <1>;
	              xlnx,gt-ch3-rx-int-data-width-c0 = <80>;
	              xlnx,gt-ch2-tx-data-encoding-c0 = "RAW";
	              xlnx,gt-ch1-tx-pll-type-c0 = "LCPLL";
	              xlnx,gt-ch3-rx-int-data-width-c1 = <80>;
	              xlnx,gt-ch2-tx-data-encoding-c1 = "RAW";
	              xlnx,gt-ch1-tx-pll-type-c1 = "LCPLL";
	              xlnx,dcmac-mode-c0 = "Coupled , MAC+PCS";
	              xlnx,port4-1588v2-clocking-c0 = "Ordinary/Boundary , Clock";
	              xlnx,dcmac-mode-c1 = "N/A";
	              xlnx,mac-port0-rx-opcode-max-gcp-c0 = <0xffff>;
	              xlnx,port4-1588v2-clocking-c1 = "Ordinary/Boundary , Clock";
	              xlnx,mac-port5-tx-opcode-gpp-c0 = <0x1>;
	              xlnx,fec-slice4-cfg-c0 = "N/A";
	              xlnx,mac-port0-rx-opcode-max-gcp-c1 = <0xffff>;
	              xlnx,mac-port5-tx-opcode-gpp-c1 = <0x1>;
	              xlnx,fec-slice4-cfg-c1 = "N/A";
	              xlnx,mac-port0-config-c0 = "100CAUI-4";
	              xlnx,mac-port0-config-c1 = "N/A";
	              xlnx,mac-port0-tx-ethertype-gpp-c0 = <0x8808>;
	              xlnx,gt-ch0-rx-line-rate-c0 = <0x9d5b34>;
	              xlnx,mac-port0-tx-ethertype-gpp-c1 = <0x8808>;
	              xlnx,gt-ch0-rx-line-rate-c1 = <0x9d5b34>;
	              xlnx,oth-pcs-port5-config1-c0 = "N/A";
	              xlnx,mac-port4-rx-opcode-gpp-c0 = <0x1>;
	              xlnx,gt-ch2-rx-line-rate-c0 = <0x9d5b34>;
	              xlnx,oth-pcs-port5-config1-c1 = "100CAUI-4";
	              xlnx,mac-port4-rx-opcode-gpp-c1 = <0x1>;
	              xlnx,gt-ch2-rx-line-rate-c1 = <0x9d5b34>;
	              xlnx,mac-port5-tx-insert-c0 = <0>;
	              xlnx,gt-ch0-rxprogdiv-freq-enable-c0;
	              xlnx,mac-port5-tx-insert-c1 = <1>;
	              xlnx,gt-ch0-rxprogdiv-freq-enable-c1;
	              xlnx,gt-ch0-rx-outclk-source-c0 = "RXPROGDIVCLK";
	              xlnx,mac-port5-rx-opcode-min-pcp-c0 = <0x0>;
	              xlnx,gt-ch0-rx-outclk-source-c1 = "RXPROGDIVCLK";
	              xlnx,mac-port5-rx-opcode-min-pcp-c1 = <0x0>;
	              xlnx,mac-port0-rx-strip-c0 = <0>;
	              xlnx,mac-port3-enable-c0 = <0>;
	              xlnx,fec-slice2-cfg-c0 = "N/A";
	              xlnx,mac-port0-rx-strip-c1 = <0>;
	              xlnx,mac-port3-enable-c1 = <1>;
	              xlnx,fec-slice2-cfg-c1 = "N/A";
	              xlnx,num-gt-channels-port3-con1 = <0>;
	              xlnx,gt-ch3-tx-outclk-source-c0 = "TXPROGDIVCLK";
	              xlnx,gt-ch2-rx-user-data-width-c0 = <80>;
	              xlnx,num-gt-channels-port3-con2 = <0>;
	              xlnx,mac-port2-preemption-c0 = <0>;
	              xlnx,gt-ch3-tx-outclk-source-c1 = "TXPROGDIVCLK";
	              xlnx,gt-ch2-rx-user-data-width-c1 = <80>;
	              xlnx,mac-port4-tx-flow-c0 = <0>;
	              xlnx,num-gt-channels-port3-con3 = <0>;
	              xlnx,mac-port2-preemption-c1 = <0>;
	              xlnx,mac-port4-tx-flow-c1 = <0>;
	              xlnx,num-gt-channels-port3-con4 = <0>;
	              xlnx,oth-pcs-port0-config4-c0 = "N/A";
	              xlnx,mac-port3-rx-pause-da-ucast-c0 = <0x0>;
	              xlnx,gt-ch3-rx-refclk-frequency-c0 = <0x13356219>;
	              xlnx,oth-pcs-port0-config4-c1 = "100CAUI-4";
	              xlnx,mac-port3-rx-pause-da-ucast-c1 = <0x0>;
	              clocks = <&misc_clk_0>, <&misc_clk_1>, <&misc_clk_2>, <&misc_clk_2>, <&misc_clk_2>, <&misc_clk_2>, <&misc_clk_0>, <&misc_clk_1>, <&misc_clk_2>, <&misc_clk_2>;
	              xlnx,num-gt-channels-port0-con1 = <0>;
	              xlnx,gt-ch3-rx-refclk-frequency-c1 = <0x9502f90>;
	              xlnx,port1-1588v2-operation-mode-c0 = "No , operation";
	              xlnx,mac-port1-tx-ethertype-ppp-c0 = <0x8808>;
	              xlnx,num-gt-channels-port0-con2 = <0>;
	              xlnx,port1-1588v2-operation-mode-c1 = "No , operation";
	              xlnx,mac-port1-tx-ethertype-ppp-c1 = <0x8808>;
	              xlnx,num-gt-channels-port0-con3 = <0>;
	              xlnx,gt-ch3-txprogdiv-freq-source-c0 = "LCPLL";
	              xlnx,num-gt-channels-port0-con4 = <0>;
	              xlnx,gt-ch3-txprogdiv-freq-source-c1 = "LCPLL";
	              xlnx,gt-ch1-rx-data-decoding-c0 = "RAW";
	              xlnx,dcmac-configuration-type = "Static , Configuration";
	              xlnx,gt-ch3-txprogdiv-freq-val-c0 = <0x266ac338>;
	              xlnx,gt-ch1-rx-data-decoding-c1 = "RAW";
	              xlnx,mac-port1-rx-opcode-max-pcp-c0 = <0xffff>;
	              xlnx,gt-ch3-txprogdiv-freq-val-c1 = <0x266ac338>;
	              xlnx,mac-port5-rx-opcode-min-gcp-c0 = <0x0>;
	              xlnx,mac-port1-rx-opcode-max-pcp-c1 = <0xffff>;
	              xlnx,gt-ch2-rx-refclk-frequency-c0 = <0x13356219>;
	              xlnx,mac-port5-rx-opcode-min-gcp-c1 = <0x0>;
	              xlnx,mac-port0-rx-flow-c0 = <1>;
	              xlnx,gt-ch2-rx-refclk-frequency-c1 = <0x9502f90>;
	              xlnx,fec-slice0-cfg-c0 = "RS(528) , CL91";
	              xlnx,mac-port0-rx-flow-c1 = <0>;
	              xlnx,fec-slice0-cfg-c1 = "N/A";
	              xlnx,gt-ch3-tx-data-encoding-c0 = "RAW";
	              xlnx,mac-port4-tx-insert-c0 = <0>;
	              xlnx,gt-ch3-tx-data-encoding-c1 = "RAW";
	              xlnx,mac-port4-tx-insert-c1 = <1>;
	              xlnx,gt-ch1-rx-refclk-frequency-c0 = <0x13356219>;
	              xlnx,mac-port3-enable-time-stamping-c0 = <0>;
	              xlnx,mac-port0-rx-etype-pcp-c0 = <0x8808>;
	              xlnx,mac-port2-rx-pause-da-mcast-c0 = <0x180 0xc2000001>;
	              xlnx,gt-ch1-rx-refclk-frequency-c1 = <0x9502f90>;
	              xlnx,mac-port5-tx-sa-ppp-c0 = <0x0>;
	              xlnx,mac-port3-enable-time-stamping-c1 = <0>;
	              xlnx,mac-port0-rx-etype-pcp-c1 = <0x8808>;
	              xlnx,mac-port2-rx-pause-da-mcast-c1 = <0x180 0xc2000001>;
	              xlnx,mac-port5-tx-sa-ppp-c1 = <0x0>;
	              xlnx,mac-port1-tx-ethertype-gpp-c0 = <0x8808>;
	              xlnx,mac-port2-config-c0 = "N/A";
	              xlnx,mac-port2-rx-etype-pcp-c0 = <0x8808>;
	              xlnx,gt-ch3-rxprogdiv-freq-source-c0 = "LCPLL";
	              xlnx,num-gt-channels = <4>;
	              xlnx,mac-port1-tx-ethertype-gpp-c1 = <0x8808>;
	              xlnx,mac-port2-config-c1 = "N/A";
	              xlnx,mac-port2-rx-etype-pcp-c1 = <0x8808>;
	              xlnx,gt-ch3-rxprogdiv-freq-source-c1 = "LCPLL";
	              xlnx,mac-port4-rx-etype-pcp-c0 = <0x8808>;
	              xlnx,mac-port4-rx-etype-pcp-c1 = <0x8808>;
	              xlnx,mac-port1-rx-opcode-max-gcp-c0 = <0xffff>;
	              xlnx,gt-ch2-rx-buffer-mode-c0 = <1>;
	              xlnx,gt-ch0-rx-refclk-frequency-c0 = <0x13356219>;
	              xlnx,gt-mode-c0 = "Custom";
	              xlnx,mac-port1-rx-opcode-max-gcp-c1 = <0xffff>;
	              xlnx,gt-ch2-rx-buffer-mode-c1 = <1>;
	              xlnx,gt-ch0-rx-refclk-frequency-c1 = <0x9502f90>;
	              xlnx,mac-port5-tx-flow-c0 = <0>;
	              xlnx,gt-mode-c1 = "Custom";
	              xlnx,gt-ch2-tx-buffer-mode-c0 = <1>;
	              xlnx,mac-port5-tx-flow-c1 = <0>;
	              xlnx,mac-port2-rx-pause-sa-c0 = <0x0>;
	              xlnx,gt-ch2-tx-buffer-mode-c1 = <1>;
	              xlnx,gt-ch1-rx-outclk-source-c0 = "RXPROGDIVCLK";
	              xlnx,oth-pcs-port1-config4-c0 = "N/A";
	              xlnx,mac-port2-rx-pause-sa-c1 = <0x0>;
	              xlnx,gt-ch1-rx-outclk-source-c1 = "RXPROGDIVCLK";
	              xlnx,oth-pcs-port1-config4-c1 = "100CAUI-4";
                      fixed-link {
                                 speed = <100000>;
                                 full-duplex;
                      };

	};

/*	mrmac_wrapper_mrmac_block_mrmac_core_0_core: mrmac@a4090000 {
			clock-names = "s_axi_aclk", "rx_axi_clk", "rx_flexif_clk", "rx_ts_clk", "tx_axi_clk", "tx_flexif_clk", "tx_ts_clk";
			//clocks = <&misc_clk_0>,  <&misc_clk_1>, <&misc_clk_1>;
			compatible = "xlnx,mrmac-1.3", "xlnx,mrmac-100g-ethernet-1.0";
			reg = <0x0 0xa4040000 0x0 0x1000>;
			xlnx,gtpll = <&cips_block_axi_gpio_gt_reset_mask>;
			xlnx,gtctrl = <&cips_block_gtctrl>;
			xlnx,gtlane = <0>;
			axistream-connected = <&axi_dma_0>;
			xlnx,mrmac-rate = <100000>;
			xlnx,flex-port0-data-rate-c0 = "100GE";
			xlnx,flex-port0-data-rate-c1 = "N/A";
			xlnx,flex-port0-enable-time-stamping-c0 = <0>;
			xlnx,flex-port0-enable-time-stamping-c1 = <0>;
			xlnx,flex-port0-mode-c0 = "PCS/BASE-R";
			xlnx,flex-port0-mode-c1 = "N/A";
			xlnx,flex-slice0-cfg-c0 = "100G (IEEE 802.3) - RS(528 514)";
			xlnx,flex-slice0-cfg-c1 = "FEC Disabled (Bypass)";
			xlnx,gt-ch0-rx-buffer-mode-c0 = <1>;
			xlnx,gt-ch0-rx-buffer-mode-c1 = <1>;
			xlnx,gt-ch0-rx-data-decoding-c0 = "RAW";
			xlnx,gt-ch0-rx-data-decoding-c1 = "RAW";
			xlnx,gt-ch0-rx-int-data-width-c0 = <80>;
			xlnx,gt-ch0-rx-int-data-width-c1 = <80>;
			xlnx,gt-ch0-rx-line-rate-c0 = "25.78125";
			xlnx,gt-ch0-rx-line-rate-c1 = "25.78125";
			xlnx,gt-ch0-rx-outclk-source-c0 = "RXPROGDIVCLK";
			xlnx,gt-ch0-rx-outclk-source-c1 = "RXPROGDIVCLK";
			xlnx,gt-ch0-rx-refclk-frequency-c0 = "322.265625";
			xlnx,gt-ch0-rx-refclk-frequency-c1 = "156.25";
			xlnx,gt-ch0-rx-user-data-width-c0 = <0x50>;
			xlnx,gt-ch0-rx-user-data-width-c1 = <0x50>;
			xlnx,gt-ch0-rxprogdiv-freq-enable-c0 = "true";
			xlnx,gt-ch0-rxprogdiv-freq-enable-c1 = "true";
			xlnx,gt-ch0-rxprogdiv-freq-source-c0 = "LCPLL";
			xlnx,gt-ch0-rxprogdiv-freq-source-c1 = "LCPLL";
			xlnx,gt-ch0-rxprogdiv-freq-val-c0 = "644.531";
			xlnx,gt-ch0-rxprogdiv-freq-val-c1 = "644.531";
			xlnx,gt-ch0-txprogdiv-freq-enable-c0 = "true";
			xlnx,gt-ch0-txprogdiv-freq-enable-c1 = "true";
			xlnx,gt-ch0-txprogdiv-freq-source-c0 = "LCPLL";
			xlnx,gt-ch0-txprogdiv-freq-source-c1 = "LCPLL";
			xlnx,mac-port0-enable-time-stamping-c0 = <0>;
			xlnx,mac-port0-enable-time-stamping-c1 = <0>;
			xlnx,mac-port0-rate-c0 = "100GE";
			xlnx,mac-port0-rate-c1 = "N/A";
			xlnx,mac-port0-rx-etype-gcp-c0 = <0x8808>;
			xlnx,mac-port0-rx-etype-gcp-c1 = <0x8808>;
			xlnx,mac-port0-rx-etype-gpp-c0 = <0x8808>;
			xlnx,mac-port0-rx-etype-gpp-c1 = <0x8808>;
			xlnx,mac-port0-rx-etype-pcp-c0 = <0x8808>;
			xlnx,mac-port0-rx-etype-pcp-c1 = <0x8808>;
			xlnx,mac-port0-rx-etype-ppp-c0 = <0x8808>;
			xlnx,mac-port0-rx-etype-ppp-c1 = <0x8808>;
			xlnx,mac-port0-rx-flow-c0 = <1>;
			xlnx,mac-port0-rx-flow-c1 = <0>;
			xlnx,mac-port0-rx-opcode-gpp-c0 = <0x0001>;
			xlnx,mac-port0-rx-opcode-gpp-c1 = <0x0001>;
			xlnx,mac-port0-rx-opcode-max-gcp-c0 = <0xFFFF>;
			xlnx,mac-port0-rx-opcode-max-gcp-c1 = <0xFFFF>;
			xlnx,mac-port0-rx-opcode-max-pcp-c0 = <0xFFFF>;
			xlnx,mac-port0-rx-opcode-max-pcp-c1 = <0xFFFF>;
			xlnx,mac-port0-rx-opcode-min-gcp-c0 = <0x0000>;
			xlnx,mac-port0-rx-opcode-min-gcp-c1 = <0x0000>;
			xlnx,mac-port0-rx-opcode-min-pcp-c0 = <0x0000>;
			xlnx,mac-port0-rx-opcode-min-pcp-c1 = <0x0000>;
			xlnx,mac-port0-rx-opcode-ppp-c0 = <0x0101>;
			xlnx,mac-port0-rx-opcode-ppp-c1 = <0x0101>;
			xlnx,mac-port0-rx-pause-da-mcast-c0 = <0x00000180 0xC2000001>;
			xlnx,mac-port0-rx-pause-da-mcast-c1 = <0x00000180 0xC2000001>;
			xlnx,mac-port0-rx-pause-da-ucast-c0 = <0x00000000 0x00000000>;
			xlnx,mac-port0-rx-pause-da-ucast-c1 = <0x00000000 0x00000000>;
			xlnx,mac-port0-rx-pause-sa-c0 = <0x00000000 0x00000000>;
			xlnx,mac-port0-rx-pause-sa-c1 = <0x00000000 0x00000000>;
			xlnx,mac-port0-tx-da-gpp-c0 = <0x00000180 0xC2000001>;
			xlnx,mac-port0-tx-da-gpp-c1 = <0x00000180 0xC2000001>;
			xlnx,mac-port0-tx-da-ppp-c0 = <0x00000180 0xC2000001>;
			xlnx,mac-port0-tx-da-ppp-c1 = <0x00000180 0xC2000001>;
			xlnx,mac-port0-tx-ethertype-gpp-c0 = <0x8808>;
			xlnx,mac-port0-tx-ethertype-gpp-c1 = <0x8808>;
			xlnx,mac-port0-tx-ethertype-ppp-c0 = <0x8808>;
			xlnx,mac-port0-tx-ethertype-ppp-c1 = <0x8808>;
			xlnx,mac-port0-tx-flow-c0 = <1>;
			xlnx,mac-port0-tx-flow-c1 = <0>;
			xlnx,mac-port0-tx-opcode-gpp-c0 = <0x0001>;
			xlnx,mac-port0-tx-opcode-gpp-c1 = <0x0001>;
			xlnx,mac-port0-tx-sa-gpp-c0 = <0x00000000 0x00000000>;
			xlnx,mac-port0-tx-sa-gpp-c1 = <0x00000000 0x00000000>;
			xlnx,mac-port0-tx-sa-ppp-c0 = <0x00000000 0x00000000>;
			xlnx,mac-port0-tx-sa-ppp-c1 = <0x00000000 0x00000000>;
			xlnx,port0-1588v2-clocking-c0 = "Ordinary/Boundary Clock";
			xlnx,port0-1588v2-clocking-c1 = "Ordinary/Boundary Clock";
			xlnx,port0-1588v2-operation-mode-c0 = "No operation";
			xlnx,port0-1588v2-operation-mode-c1 = "No operation";
		};*/
};
